# STM32L4x2 register map
File version: 1.6
CPU: CM4 r1p0, little endian, no MPU, no FPU, 3 interrupt priority bits
Registers are 32-bit, read-write, reset 0x0 unless marked. A register's access mark holds for its fields unless they carry their own. Offsets are from the block's base; lines under a group give offsets from that group; [hi:lo] are bit positions; {n}, {i} and the like mark numbered series; 'fields as' and 'values as' point back to an identical list; <NAME> marks a mode.

## Memory map
0x40006800 USB size 0x400 — Universal serial bus full-speed device interface
0x40020000 DMA1 size 0x400 — Direct memory access controller
0x40020400 DMA2 size 0x400
0xE000E008 SCB_ACTRL size 0x5 — System control block ACTLR

## Interrupts
11 DMA1_CH1 (DMA1) — DMA1 Channel1 global interrupt
12 DMA1_CH2 (DMA1) — DMA1 Channel2 global interrupt
13 DMA1_CH3 (DMA1) — DMA1 Channel3 interrupt
14 DMA1_CH4 (DMA1) — DMA1 Channel4 interrupt
15 DMA1_CH5 (DMA1) — DMA1 Channel5 interrupt
16 DMA1_CH6 (DMA1) — DMA1 Channel6 interrupt
17 DMA1_CH7 (DMA1) — DMA1 Channel 7 interrupt
56 DMA2_CH1 (DMA2) — DMA2 Channel 1 global Interrupt
57 DMA2_CH2 (DMA2) — DMA2 Channel 2 global Interrupt
58 DMA2_CH3 (DMA2) — DMA2 Channel 3 global Interrupt
59 DMA2_CH4 (DMA2) — DMA2 Channel 4 global Interrupt
60 DMA2_CH5 (DMA2) — DMA2 Channel 5 global Interrupt
68 DMA2_CH6 (DMA2) — DMA2 Channel 6 global Interrupt
69 DMA2_CH7 (DMA2) — DMA2 Channel 7 global Interrupt

## DMA1 — Direct memory access controller
Base 0x40020000
Same registers: DMA2 0x40020400
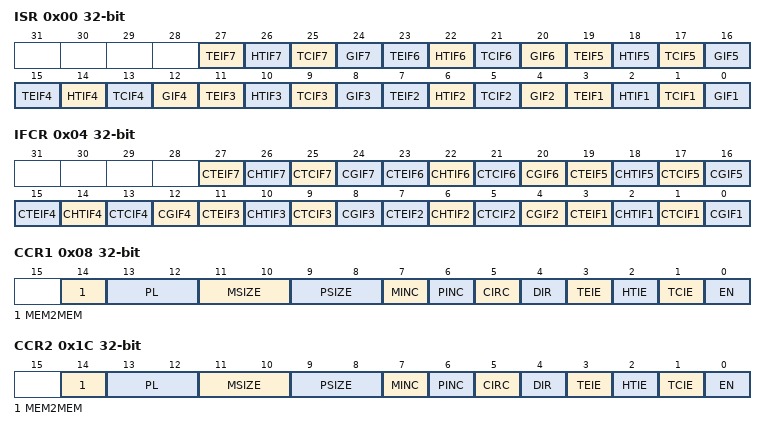
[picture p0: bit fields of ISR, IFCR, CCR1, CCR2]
0x00 ISR ro — interrupt status register
  [4n-1] TEIF{n} (n=1..7) — Channel x transfer error flag (x = 1 ..7)
  [4n-2] HTIF{n} (n=1..7) — Channel x half transfer flag (x = 1 ..7)
  [4n-3] TCIF{n} (n=1..7) — Channel x transfer complete flag (x = 1 ..7)
  [4n-4] GIF{n} (n=1..7) — Channel x global interrupt flag (x = 1 ..7)
0x04 IFCR wo — interrupt flag clear register
  [4n-1] CTEIF{n} (n=1..7) — Channel x transfer error clear (x = 1 ..7)
  [4n-2] CHTIF{n} (n=1..7) — Channel x half transfer clear (x = 1 ..7)
  [4n-3] CTCIF{n} (n=1..7) — Channel x transfer complete clear (x = 1 ..7)
  [4n-4] CGIF{n} (n=1..7) — Channel x global interrupt clear (x = 1 ..7)
0x08 CCR1 — channel x configuration register
  [14] MEM2MEM — Memory to memory mode
  [13:12] PL — Channel priority level
  [11:10] MSIZE — Memory size
  [9:8] PSIZE — Peripheral size
  [7] MINC — Memory increment mode
  [6] PINC — Peripheral increment mode
  [5] CIRC — Circular mode
  [4] DIR — Data transfer direction
  [3] TEIE — Transfer error interrupt enable
  [2] HTIE — Half transfer interrupt enable
  [1] TCIE — Transfer complete interrupt enable
  [0] EN — Channel enable
0x0C CNDTR1 — channel x number of data register
  [15:0] NDT — Number of data to transfer
0x10 CPAR1 — channel x peripheral address register
  [31:0] PA — Peripheral address
{0x0+0x14*i} CMAR{i} (i=1..7) — channel x memory address register
  [31:0] MA — Memory address
0x1C CCR2 — channel x configuration register
  fields as CCR1
0x20 CNDTR2 — channel x number of data register
  [15:0] NDT — Number of data to transfer
0x24 CPAR2 — channel x peripheral address register
  [31:0] PA — Peripheral address
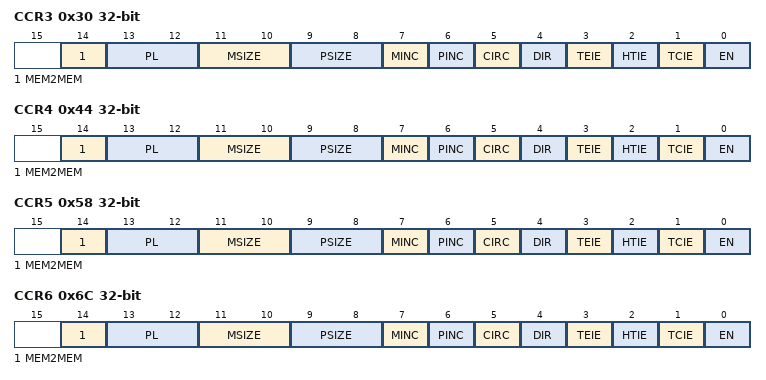
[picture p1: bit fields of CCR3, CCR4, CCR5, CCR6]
0x30 CCR3 — channel x configuration register
  fields as CCR1
0x34 CNDTR3 — channel x number of data register
  [15:0] NDT — Number of data to transfer
0x38 CPAR3 — channel x peripheral address register
  [31:0] PA — Peripheral address
0x44 CCR4 — channel x configuration register
  fields as CCR1
0x48 CNDTR4 — channel x number of data register
  [15:0] NDT — Number of data to transfer
0x4C CPAR4 — channel x peripheral address register
  [31:0] PA — Peripheral address
0x58 CCR5 — channel x configuration register
  fields as CCR1
0x5C CNDTR5 — channel x number of data register
  [15:0] NDT — Number of data to transfer
0x60 CPAR5 — channel x peripheral address register
  [31:0] PA — Peripheral address
0x6C CCR6 — channel x configuration register
  fields as CCR1
0x70 CNDTR6 — channel x number of data register
  [15:0] NDT — Number of data to transfer
0x74 CPAR6 — channel x peripheral address register
  [31:0] PA — Peripheral address
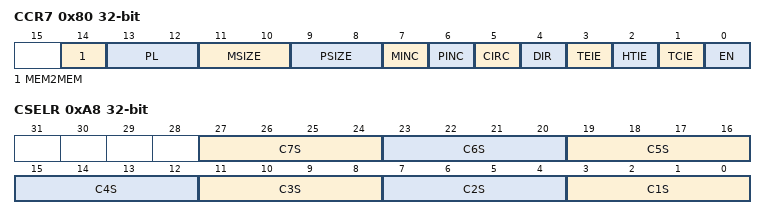
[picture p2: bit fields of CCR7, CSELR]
0x80 CCR7 — channel x configuration register
  fields as CCR1
0x84 CNDTR7 — channel x number of data register
  [15:0] NDT — Number of data to transfer
0x88 CPAR7 — channel x peripheral address register
  [31:0] PA — Peripheral address
0xA8 CSELR — channel selection register
  [4n-1:4n-4] C{n}S (n=1..7) — DMA channel {n} selection

## USB — Universal serial bus full-speed device interface
Base 0x40006800
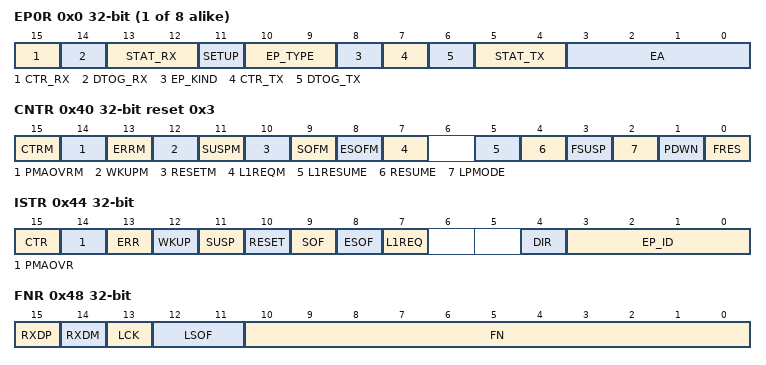
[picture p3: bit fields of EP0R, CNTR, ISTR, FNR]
{0x0+4i} EP{i}R (i=0..7) — endpoint {i} register
  [15] CTR_RX — Correct transfer for reception
  [14] DTOG_RX — Data Toggle, for reception transfers
  [13:12] STAT_RX — Status bits, for reception transfers
  [11] SETUP — Setup transaction completed
  [10:9] EP_TYPE — Endpoint type
  [8] EP_KIND — Endpoint kind
  [7] CTR_TX — Correct Transfer for transmission
  [6] DTOG_TX — Data Toggle, for transmission transfers
  [5:4] STAT_TX — Status bits, for transmission transfers
  [3:0] EA — Endpoint address
0x40 CNTR reset 0x3 — control register
  [15] CTRM — Correct transfer interrupt mask
  [14] PMAOVRM — Packet memory area over / underrun interrupt mask
  [13] ERRM — Error interrupt mask
  [12] WKUPM — Wakeup interrupt mask
  [11] SUSPM — Suspend mode interrupt mask
  [10] RESETM — USB reset interrupt mask
  [9] SOFM — Start of frame interrupt mask
  [8] ESOFM — Expected start of frame interrupt mask
  [7] L1REQM — LPM L1 state request interrupt mask
  [5] L1RESUME — LPM L1 Resume request
  [4] RESUME — Resume request
  [3] FSUSP — Force suspend
  [2] LPMODE — Low-power mode
  [1] PDWN — Power down
  [0] FRES — Force USB Reset
0x44 ISTR access per field — interrupt status register
  [15] CTR ro — Correct transfer
  [14] PMAOVR rw — Packet memory area over / underrun
  [13] ERR rw — Error
  [12] WKUP rw — Wakeup
  [11] SUSP rw — Suspend mode request
  [10] RESET rw — reset request
  [9] SOF rw — start of frame
  [8] ESOF rw — Expected start frame
  [7] L1REQ rw — LPM L1 state request
  [4] DIR ro — Direction of transaction
  [3:0] EP_ID ro — Endpoint Identifier
0x48 FNR ro — frame number register
  [15] RXDP — Receive data + line status
  [14] RXDM — Receive data - line status
  [13] LCK — Locked
  [12:11] LSOF — Lost SOF
  [10:0] FN — Frame number
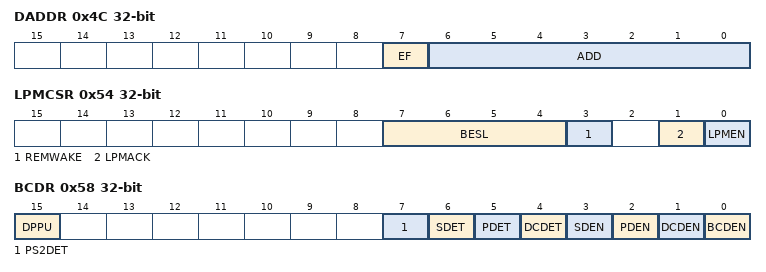
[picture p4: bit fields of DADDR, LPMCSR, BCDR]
0x4C DADDR — device address
  [7] EF — Enable function
  [6:0] ADD — Device address
0x50 BTABLE — Buffer table address
  [15:3] BTABLE — Buffer table
0x54 LPMCSR access per field — LPM control and status register
  [7:4] BESL ro — BESL value
  [3] REMWAKE ro — bRemoteWake value
  [1] LPMACK rw — LPM Token acknowledge enable
  [0] LPMEN rw — LPM support enable
0x58 BCDR access per field — Battery charging detector
  [15] DPPU rw — DP pull-up control
  [7] PS2DET ro — DM pull-up detection status
  [6] SDET ro — Secondary detection
  [5] PDET ro — Primary detection
  [4] DCDET ro — Data contact detection
  [3] SDEN rw — Secondary detection
  [2] PDEN rw — Primary detection
  [1] DCDEN rw — Data contact detection
  [0] BCDEN rw — Battery charging detector

## SCB_ACTRL — System control block ACTLR
Base 0xE000E008
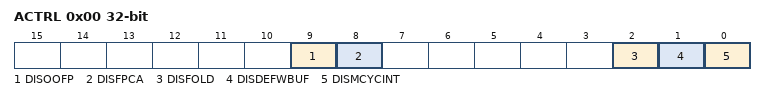
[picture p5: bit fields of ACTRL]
0x00 ACTRL — Auxiliary control register
  [9] DISOOFP, [8] DISFPCA, [2] DISFOLD, [1] DISDEFWBUF, [0] DISMCYCINT
